# STM32L4S9xx register map
File version: 1.0
Registers are 32-bit, access not given, reset 0x0 unless marked. A register's access mark holds for its fields unless they carry their own. Offsets are from the block's base; [hi:lo] are bit positions; {n}, {i} and the like mark numbered series.

## GPIOA
Base 0x48000000
Same registers: GPIOB 0x48000400, GPIOC 0x48000800, GPIOD 0x48000C00, GPIOE 0x48001000, GPIOF 0x48001400, GPIOG 0x48001800, GPIOH 0x48001C00, GPIOI 0x48002000
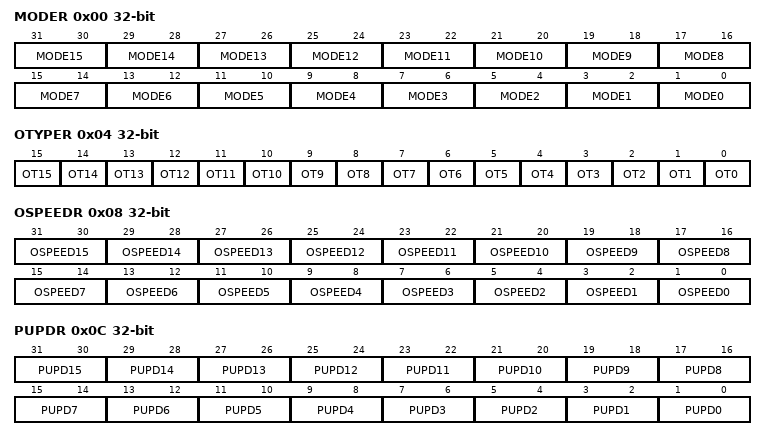
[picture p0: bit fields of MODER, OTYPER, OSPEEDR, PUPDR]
0x00 MODER
  [2n+1:2n] MODE{n} (n=0..15)
0x04 OTYPER
  [n] OT{n} (n=0..15)
0x08 OSPEEDR
  [2n+1:2n] OSPEED{n} (n=0..15)
0x0C PUPDR
  [2n+1:2n] PUPD{n} (n=0..15)
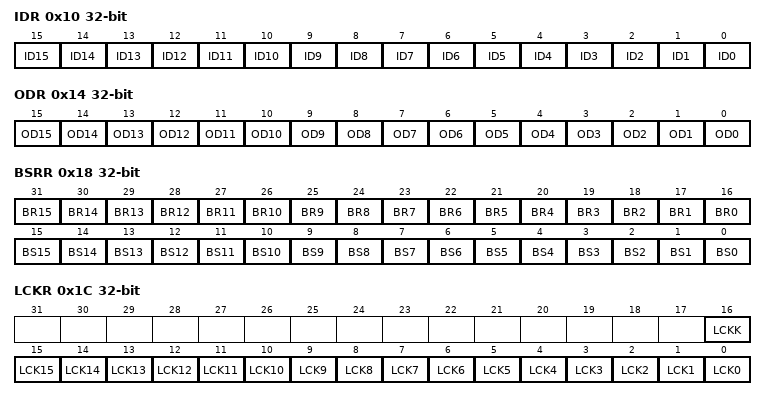
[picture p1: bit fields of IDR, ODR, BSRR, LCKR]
0x10 IDR
  [n] ID{n} (n=0..15)
0x14 ODR
  [n] OD{n} (n=0..15)
0x18 BSRR
  [n+16] BR{n} (n=0..15), [n] BS{n} (n=0..15)
0x1C LCKR
  [16] LCKK, [n] LCK{n} (n=0..15)
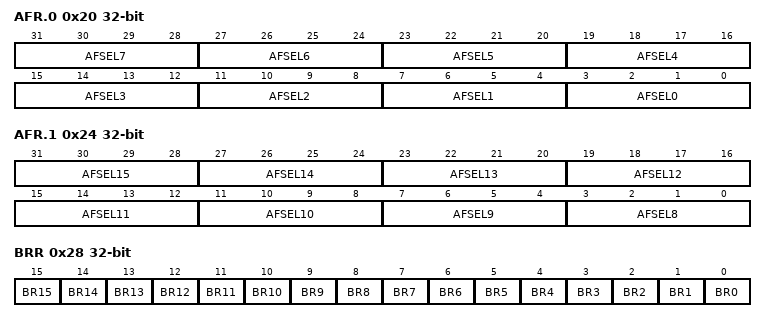
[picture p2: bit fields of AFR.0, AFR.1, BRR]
0x20 AFR.0
  [4n+3:4n] AFSEL{n} (n=0..7)
0x24 AFR.1
  [4n-29:4n-32] AFSEL{n} (n=8..15)
0x28 BRR
  [n] BR{n} (n=0..15)

## USB_OTG_FS
Base 0x50000000
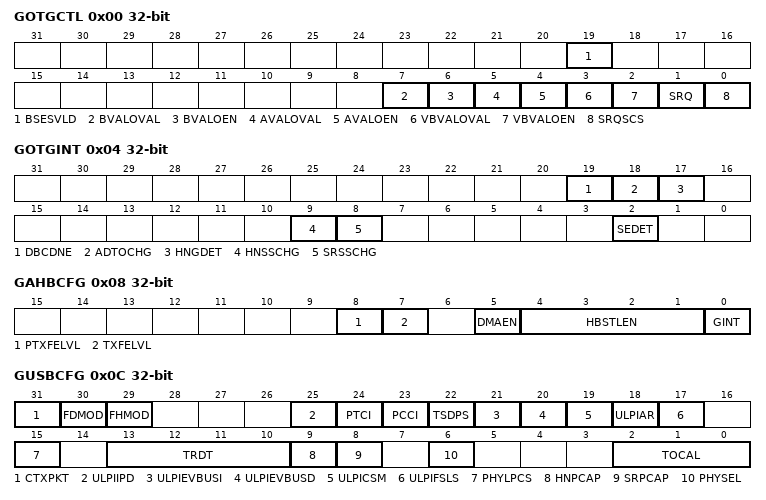
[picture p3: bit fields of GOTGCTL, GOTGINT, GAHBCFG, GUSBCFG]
0x00 GOTGCTL
  [19] BSESVLD, [7] BVALOVAL, [6] BVALOEN, [5] AVALOVAL, [4] AVALOEN, [3] VBVALOVAL, [2] VBVALOEN, [1] SRQ, [0] SRQSCS
0x04 GOTGINT
  [19] DBCDNE, [18] ADTOCHG, [17] HNGDET, [9] HNSSCHG, [8] SRSSCHG, [2] SEDET
0x08 GAHBCFG
  [8] PTXFELVL, [7] TXFELVL, [5] DMAEN, [4:1] HBSTLEN, [0] GINT
0x0C GUSBCFG
  [31] CTXPKT, [30] FDMOD, [29] FHMOD, [25] ULPIIPD, [24] PTCI, [23] PCCI, [22] TSDPS, [21] ULPIEVBUSI, [20] ULPIEVBUSD, [19] ULPICSM, [18] ULPIAR, [17] ULPIFSLS, [15] PHYLPCS, [13:10] TRDT, [9] HNPCAP, [8] SRPCAP, [6] PHYSEL, [2:0] TOCAL
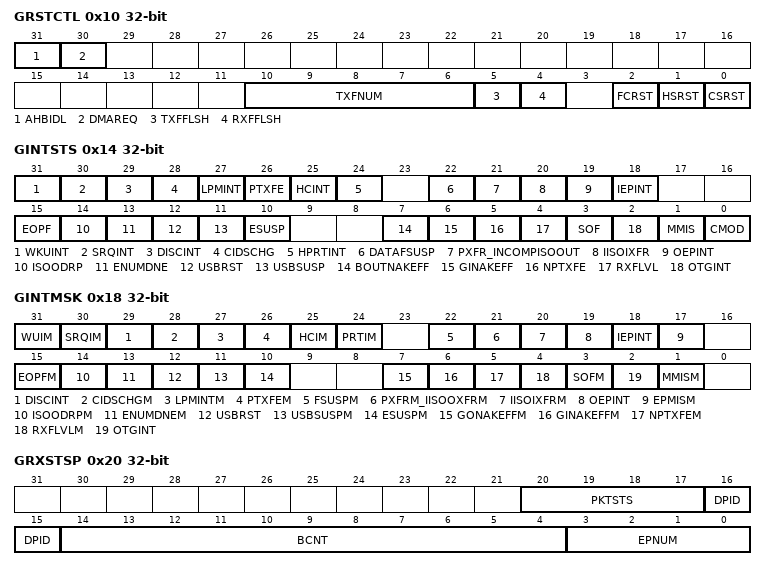
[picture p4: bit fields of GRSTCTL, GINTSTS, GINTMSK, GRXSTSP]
0x10 GRSTCTL
  [31] AHBIDL, [30] DMAREQ, [10:6] TXFNUM, [5] TXFFLSH, [4] RXFFLSH, [2] FCRST, [1] HSRST, [0] CSRST
0x14 GINTSTS
  [31] WKUINT, [30] SRQINT, [29] DISCINT, [28] CIDSCHG, [27] LPMINT, [26] PTXFE, [25] HCINT, [24] HPRTINT, [22] DATAFSUSP, [21] PXFR_INCOMPISOOUT, [20] IISOIXFR, [19] OEPINT, [18] IEPINT, [15] EOPF, [14] ISOODRP, [13] ENUMDNE, [12] USBRST, [11] USBSUSP, [10] ESUSP, [7] BOUTNAKEFF, [6] GINAKEFF, [5] NPTXFE, [4] RXFLVL, [3] SOF, [2] OTGINT, [1] MMIS, [0] CMOD
0x18 GINTMSK
  [31] WUIM, [30] SRQIM, [29] DISCINT, [28] CIDSCHGM, [27] LPMINTM, [26] PTXFEM, [25] HCIM, [24] PRTIM, [22] FSUSPM, [21] PXFRM_IISOOXFRM, [20] IISOIXFRM, [19] OEPINT, [18] IEPINT, [17] EPMISM, [15] EOPFM, [14] ISOODRPM, [13] ENUMDNEM, [12] USBRST, [11] USBSUSPM, [10] ESUSPM, [7] GONAKEFFM, [6] GINAKEFFM, [5] NPTXFEM, [4] RXFLVLM, [3] SOFM, [2] OTGINT, [1] MMISM
0x1C GRXSTSR
0x20 GRXSTSP
  [20:17] PKTSTS, [16:15] DPID, [14:4] BCNT, [3:0] EPNUM
0x24 GRXFSIZ
  [15:0] RXFD
0x28 DIEPTXF0_HNPTXFSIZ
0x2C HNPTXSTS
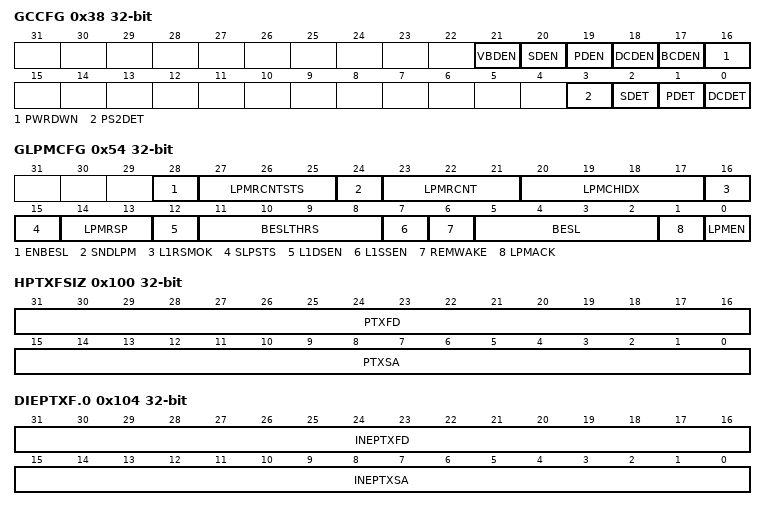
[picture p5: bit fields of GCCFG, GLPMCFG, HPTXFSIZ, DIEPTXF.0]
0x38 GCCFG
  [21] VBDEN, [20] SDEN, [19] PDEN, [18] DCDEN, [17] BCDEN, [16] PWRDWN, [3] PS2DET, [2] SDET, [1] PDET, [0] DCDET
0x3C CID
  [31:0] PRODUCT_ID
0x40 GSNPSID
{0x40+4i} GHWCFG{i} (i=1..3)
0x54 GLPMCFG
  [28] ENBESL, [27:25] LPMRCNTSTS, [24] SNDLPM, [23:21] LPMRCNT, [20:17] LPMCHIDX, [16] L1RSMOK, [15] SLPSTS, [14:13] LPMRSP, [12] L1DSEN, [11:8] BESLTHRS, [7] L1SSEN, [6] REMWAKE, [5:2] BESL, [1] LPMACK, [0] LPMEN
0x58 GPWRDN
  [6] DISABLEVBUS
0x5C GDFIFOCFG
0x60 GADPCTL
0x100 HPTXFSIZ
  [31:16] PTXFD, [15:0] PTXSA
0x104 DIEPTXF.0
  [31:16] INEPTXFD, [15:0] INEPTXSA
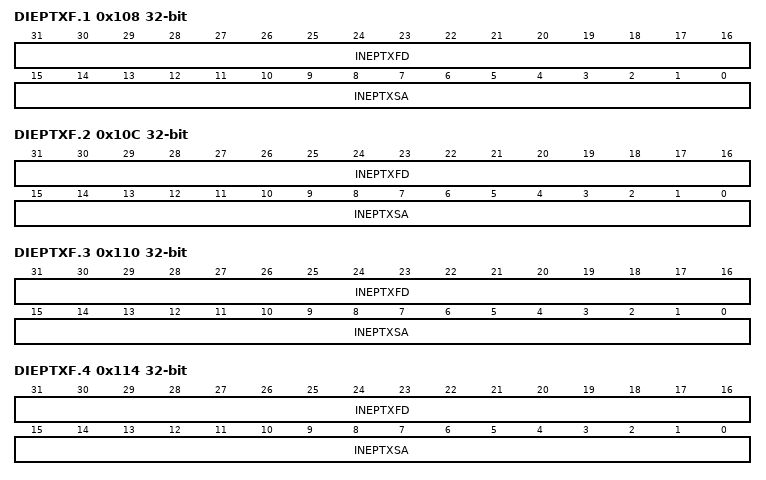
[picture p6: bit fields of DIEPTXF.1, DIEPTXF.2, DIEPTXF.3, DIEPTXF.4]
0x108 DIEPTXF.1
  [31:16] INEPTXFD, [15:0] INEPTXSA
0x10C DIEPTXF.2
  [31:16] INEPTXFD, [15:0] INEPTXSA
0x110 DIEPTXF.3
  [31:16] INEPTXFD, [15:0] INEPTXSA
0x114 DIEPTXF.4
  [31:16] INEPTXFD, [15:0] INEPTXSA
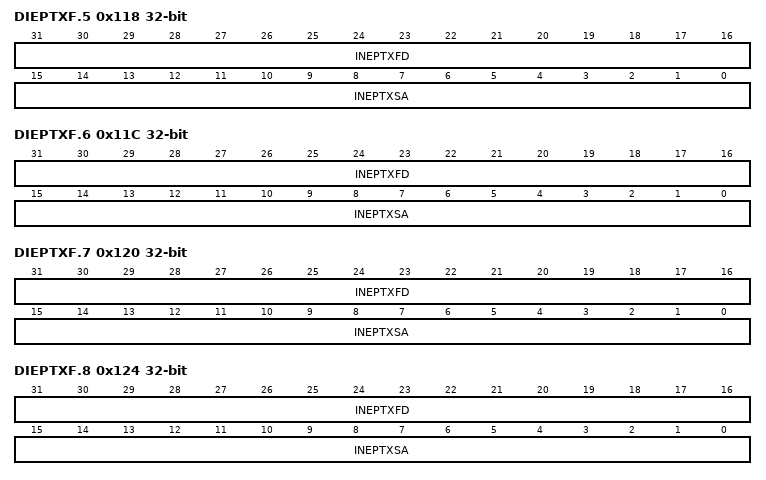
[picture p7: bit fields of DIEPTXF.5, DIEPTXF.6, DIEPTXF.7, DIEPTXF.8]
0x118 DIEPTXF.5
  [31:16] INEPTXFD, [15:0] INEPTXSA
0x11C DIEPTXF.6
  [31:16] INEPTXFD, [15:0] INEPTXSA
0x120 DIEPTXF.7
  [31:16] INEPTXFD, [15:0] INEPTXSA
0x124 DIEPTXF.8
  [31:16] INEPTXFD, [15:0] INEPTXSA
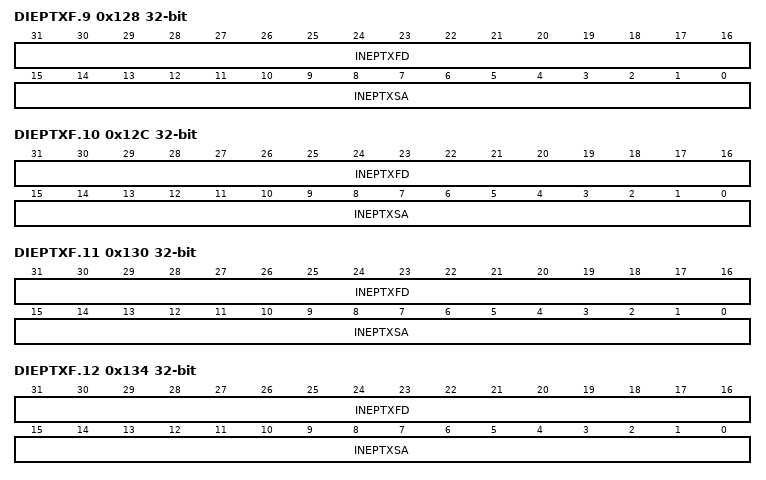
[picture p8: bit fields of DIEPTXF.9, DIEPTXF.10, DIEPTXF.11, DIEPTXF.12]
0x128 DIEPTXF.9
  [31:16] INEPTXFD, [15:0] INEPTXSA
0x12C DIEPTXF.10
  [31:16] INEPTXFD, [15:0] INEPTXSA
0x130 DIEPTXF.11
  [31:16] INEPTXFD, [15:0] INEPTXSA
0x134 DIEPTXF.12
  [31:16] INEPTXFD, [15:0] INEPTXSA
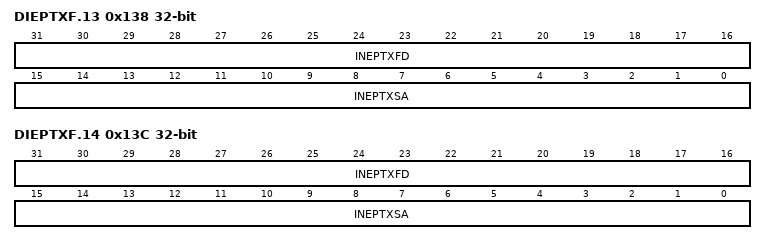
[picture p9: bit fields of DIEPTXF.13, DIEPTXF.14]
0x138 DIEPTXF.13
  [31:16] INEPTXFD, [15:0] INEPTXSA
0x13C DIEPTXF.14
  [31:16] INEPTXFD, [15:0] INEPTXSA

## ADC1
Base 0x50040000
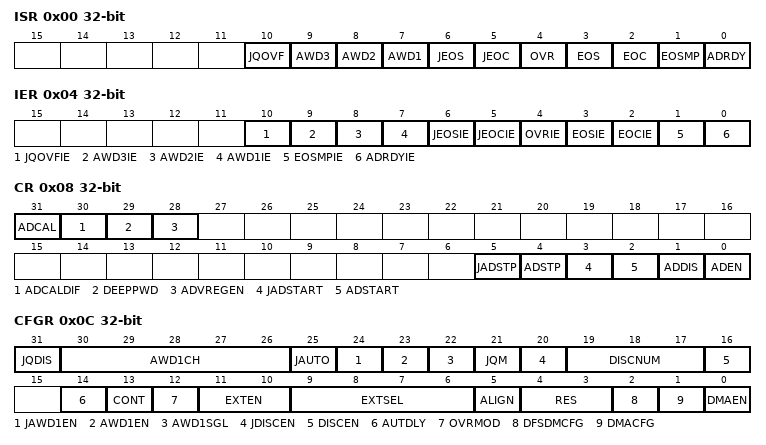
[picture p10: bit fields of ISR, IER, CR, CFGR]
0x00 ISR
  [10] JQOVF, [9] AWD3, [8] AWD2, [7] AWD1, [6] JEOS, [5] JEOC, [4] OVR, [3] EOS, [2] EOC, [1] EOSMP, [0] ADRDY
0x04 IER
  [10] JQOVFIE, [9] AWD3IE, [8] AWD2IE, [7] AWD1IE, [6] JEOSIE, [5] JEOCIE, [4] OVRIE, [3] EOSIE, [2] EOCIE, [1] EOSMPIE, [0] ADRDYIE
0x08 CR
  [31] ADCAL, [30] ADCALDIF, [29] DEEPPWD, [28] ADVREGEN, [5] JADSTP, [4] ADSTP, [3] JADSTART, [2] ADSTART, [1] ADDIS, [0] ADEN
0x0C CFGR
  [31] JQDIS, [30:26] AWD1CH, [25] JAUTO, [24] JAWD1EN, [23] AWD1EN, [22] AWD1SGL, [21] JQM, [20] JDISCEN, [19:17] DISCNUM, [16] DISCEN, [14] AUTDLY, [13] CONT, [12] OVRMOD, [11:10] EXTEN, [9:6] EXTSEL, [5] ALIGN, [4:3] RES, [2] DFSDMCFG, [1] DMACFG, [0] DMAEN
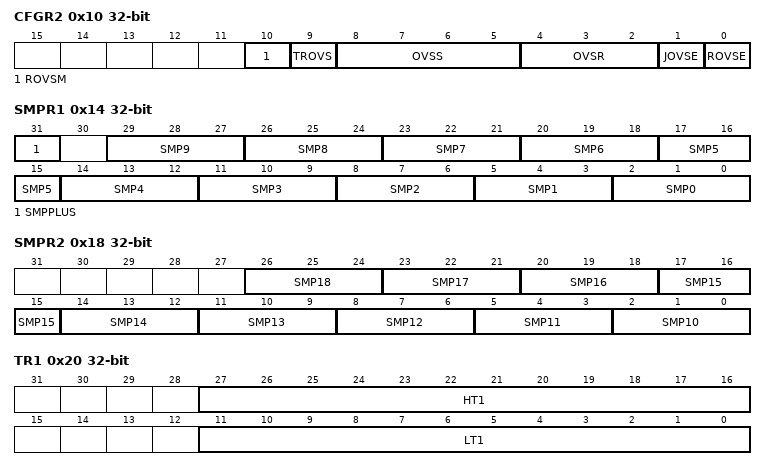
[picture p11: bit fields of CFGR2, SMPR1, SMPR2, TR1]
0x10 CFGR2
  [10] ROVSM, [9] TROVS, [8:5] OVSS, [4:2] OVSR, [1] JOVSE, [0] ROVSE
0x14 SMPR1
  [31] SMPPLUS, [3n+2:3n] SMP{n} (n=0..9)
0x18 SMPR2
  [3n-28:3n-30] SMP{n} (n=10..18)
0x20 TR1
  [27:16] HT1, [11:0] LT1
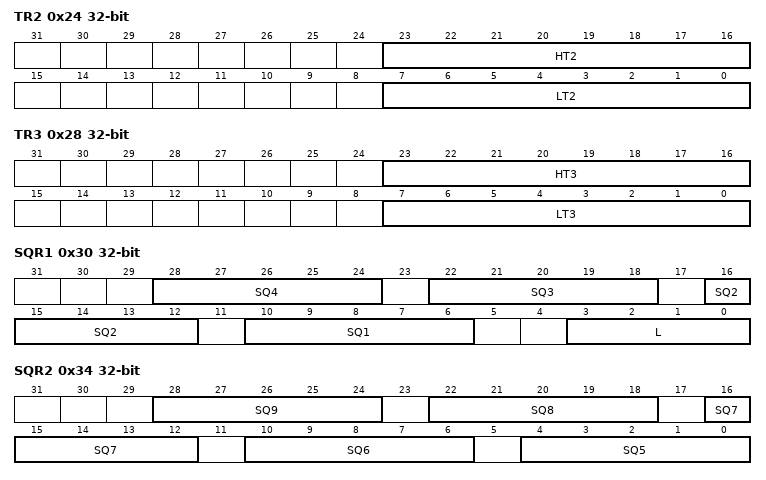
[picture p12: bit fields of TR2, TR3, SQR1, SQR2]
0x24 TR2
  [23:16] HT2, [7:0] LT2
0x28 TR3
  [23:16] HT3, [7:0] LT3
0x30 SQR1
  [6n+4:6n] SQ{n} (n=1..4), [3:0] L
0x34 SQR2
  [6n-26:6n-30] SQ{n} (n=5..9)
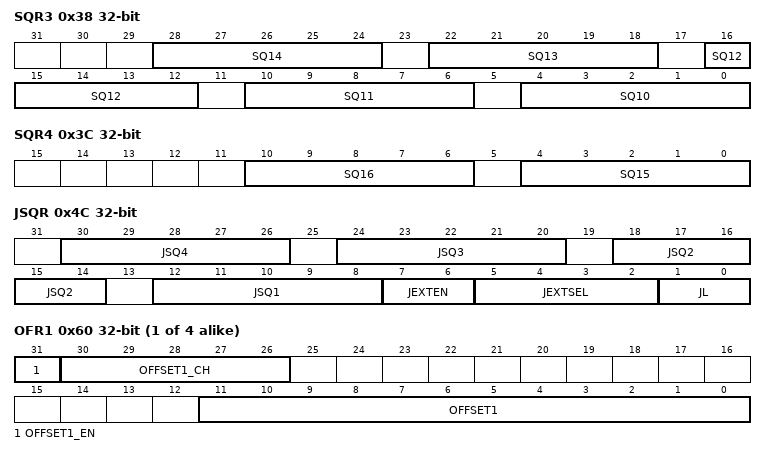
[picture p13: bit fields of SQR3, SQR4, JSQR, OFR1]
0x38 SQR3
  [6n-56:6n-60] SQ{n} (n=10..14)
0x3C SQR4
  [10:6] SQ16, [4:0] SQ15
0x40 DR
  [15:0] RDATA
0x4C JSQR
  [6n+6:6n+2] JSQ{n} (n=1..4), [7:6] JEXTEN, [5:2] JEXTSEL, [1:0] JL
{0x5C+4i} OFR{i} (i=1..4)
  [31] OFFSET{i}_EN, [30:26] OFFSET{i}_CH, [11:0] OFFSET{i}
{0x7C+4i} JDR{i} (i=1..4)
  [15:0] JDATA
0xA0 AWD2CR
  [18:0] AWD2CH
0xA4 AWD3CR
  [18:0] AWD3CH
0xB0 DIFSEL
  [18:0] DIFSEL
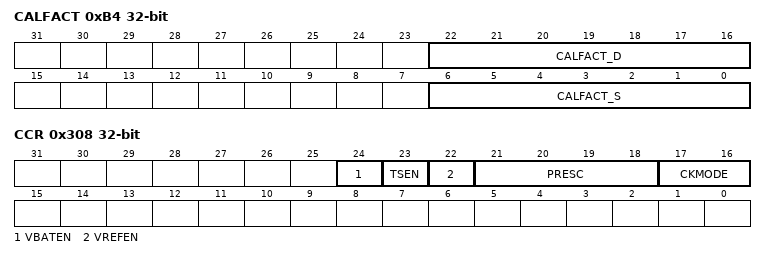
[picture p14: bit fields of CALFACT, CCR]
0xB4 CALFACT
  [22:16] CALFACT_D, [6:0] CALFACT_S
0x308 CCR
  [24] VBATEN, [23] TSEN, [22] VREFEN, [21:18] PRESC, [17:16] CKMODE
